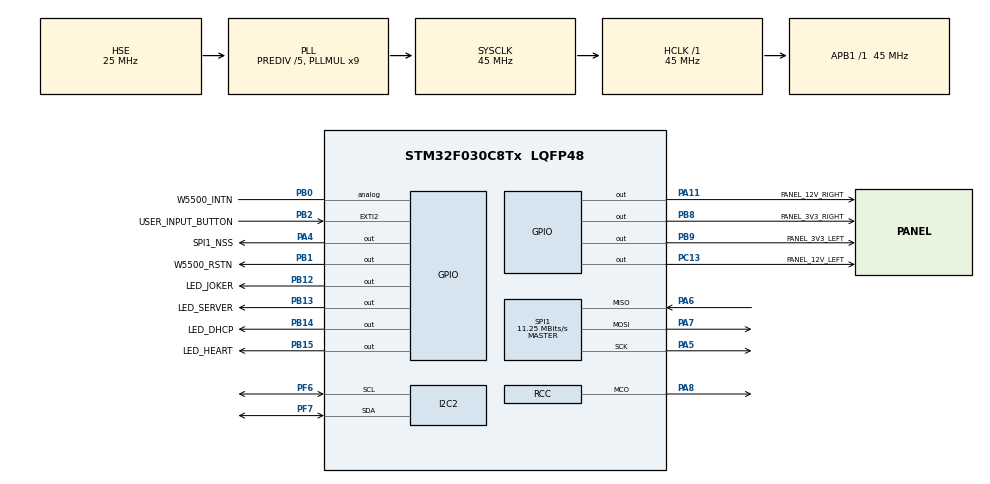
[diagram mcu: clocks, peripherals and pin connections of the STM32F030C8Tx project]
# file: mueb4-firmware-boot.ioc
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I2C2.I2C_Fall_Time=0
I2C2.I2C_Rise_Time=0
I2C2.Speed=100
I2C2.Timing=0xC0000E12
Mcu.Family=STM32F0
Mcu.Name=STM32F030C8Tx
Mcu.Package=LQFP48
Mcu.UserConstants=PRESCALER,45000 - 1;SECOND,1000 - 1
NVIC.EXTI2_3_IRQn=true\:3\:0\:true\:false\:true\:true\:true\:true
NVIC.TIM6_IRQn=true\:2\:0\:true\:false\:true\:true\:true\:true
PA0.GPIO_Label=PANEL_ADC_3V3_LEFT
PA0.GPIO_Mode=GPIO_MODE_ANALOG
PA0.GPIO_PuPd=GPIO_NOPULL
PA0.Signal=ADC_IN0
PA1.GPIO_Label=PANEL_ADC_3V3_RIGHT
PA1.GPIO_Mode=GPIO_MODE_ANALOG
PA1.GPIO_PuPd=GPIO_NOPULL
PA1.Signal=ADC_IN1
PA10.GPIO_Label=PANEL_RX_RIGHT
PA10.GPIO_PuPd=GPIO_PULLUP
PA10.GPIO_Speed=GPIO_SPEED_FREQ_HIGH
PA10.Signal=USART1_RX
PA11.GPIO_Label=PANEL_12V_RIGHT
PA11.Signal=GPIO_Output
PA13.Mode=Serial_Wire
PA13.Signal=SYS_SWDIO
PA14.Mode=Serial_Wire
PA14.Signal=SYS_SWCLK
PA2.GPIO_Label=PANEL_TX_LEFT
PA2.GPIO_Speed=GPIO_SPEED_FREQ_HIGH
PA2.Signal=USART2_TX
PA3.GPIO_Label=PANEL_RX_LEFT
PA3.GPIO_PuPd=GPIO_PULLUP
PA3.GPIO_Speed=GPIO_SPEED_FREQ_HIGH
PA3.Signal=USART2_RX
PA4.GPIO_Label=SPI1_NSS
PA4.Signal=GPIO_Output
PA5.GPIO_PuPd=GPIO_PULLUP
PA5.GPIO_Speed=GPIO_SPEED_FREQ_HIGH
PA5.Mode=Full_Duplex_Master
PA5.Signal=SPI1_SCK
PA6.GPIO_PuPd=GPIO_PULLUP
PA6.GPIO_Speed=GPIO_SPEED_FREQ_HIGH
PA6.Mode=Full_Duplex_Master
PA6.Signal=SPI1_MISO
PA7.GPIO_PuPd=GPIO_PULLUP
PA7.GPIO_Speed=GPIO_SPEED_FREQ_HIGH
PA7.Mode=Full_Duplex_Master
PA7.Signal=SPI1_MOSI
PA8.Mode=Clock-out
PA8.Signal=RCC_MCO
PA9.GPIO_Label=PANEL_TX_RIGHT
PA9.GPIO_Speed=GPIO_SPEED_FREQ_HIGH
PA9.Signal=USART1_TX
PB0.GPIO_Label=W5500_INTN
PB0.GPIO_Mode=GPIO_MODE_ANALOG
PB0.GPIO_PuPd=GPIO_NOPULL
PB0.Signal=GPIO_Analog
PB1.GPIO_Label=W5500_RSTN
PB1.PinState=GPIO_PIN_SET
PB1.Signal=GPIO_Output
PB12.GPIO_Label=LED_JOKER
PB12.Signal=GPIO_Output
PB13.GPIO_Label=LED_SERVER
PB13.Signal=GPIO_Output
PB14.GPIO_Label=LED_DHCP
PB14.Signal=GPIO_Output
PB15.GPIO_Label=LED_HEART
PB15.Signal=GPIO_Output
PB2.GPIO_Label=USER_INPUT_BUTTON
PB2.GPIO_PuPd=GPIO_PULLUP
PB2.Signal=GPXTI2
PB8.GPIO_Label=PANEL_3V3_RIGHT
PB8.GPIO_Speed=GPIO_SPEED_FREQ_LOW
PB8.PinState=GPIO_PIN_SET
PB8.Signal=GPIO_Output
PB9.GPIO_Label=PANEL_3V3_LEFT
PB9.GPIO_Speed=GPIO_SPEED_FREQ_LOW
PB9.PinState=GPIO_PIN_SET
PB9.Signal=GPIO_Output
PC13.GPIO_Label=PANEL_12V_LEFT
PC13.Signal=GPIO_Output
PF0-OSC_IN.Mode=HSE-External-Oscillator
PF0-OSC_IN.Signal=RCC_OSC_IN
PF1-OSC_OUT.Mode=HSE-External-Oscillator
PF1-OSC_OUT.Signal=RCC_OSC_OUT
PF6.GPIO_Pu=GPIO_PULLUP
PF6.GPIO_Speed=GPIO_SPEED_FREQ_HIGH
PF6.Mode=I2C
PF6.Signal=I2C2_SCL
PF7.GPIO_Pu=GPIO_PULLUP
PF7.GPIO_Speed=GPIO_SPEED_FREQ_HIGH
PF7.Mode=I2C
PF7.Signal=I2C2_SDA
ProjectManager.HeapSize=0x200
ProjectManager.StackSize=0x400
ProjectManager.TargetToolchain=STM32CubeIDE
RCC.AHBFreq_Value=45000000
RCC.APB1Freq_Value=45000000
RCC.APB1TimFreq_Value=45000000
RCC.EnbaleCSS=true
RCC.HCLKFreq_Value=45000000
RCC.HSE_VALUE=25000000
RCC.PLLDivider=RCC_PREDIV_DIV5
RCC.PLLMUL=RCC_PLL_MUL9
RCC.PLLSourceVirtual=RCC_PLLSOURCE_HSE
RCC.RCC_MCOSource=RCC_MCO1SOURCE_HSE
RCC.SYSCLKFreq_VALUE=45000000
RCC.SYSCLKSource=RCC_SYSCLKSOURCE_PLLCLK
RCC.Usart1ClockSelection=RCC_USART1CLKSOURCE_HSI
SPI1.BaudRatePrescaler=SPI_BAUDRATEPRESCALER_4
SPI1.CLKPolarity=SPI_POLARITY_LOW
SPI1.CalculateBaudRate=11.25 MBits/s
SPI1.DataSize=SPI_DATASIZE_8BIT
SPI1.Direction=SPI_DIRECTION_2LINES
SPI1.Mode=SPI_MODE_MASTER
SPI1.NSSPMode=SPI_NSS_PULSE_DISABLE
SPI1.VirtualType=VM_MASTER
TIM6.Period=SECOND
TIM6.Prescaler=PRESCALER
VP_TIM6_VS_ClockSourceINT.Mode=Enable_Timer
board=mueb4-firmware

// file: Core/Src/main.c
/* USER CODE BEGIN Header */
/**
 ******************************************************************************
 * @file           : main.c
 * @brief          : Main program body
 ******************************************************************************
 * @attention
 *
 * Copyright (c) 2022 STMicroelectronics.
 * All rights reserved.
 *
 * This software is licensed under terms that can be found in the LICENSE file
 * in the root directory of this software component.
 * If no LICENSE file comes with this software, it is provided AS-IS.
 *
 ******************************************************************************
 */
/* USER CODE END Header */
#include "main.h"
#include "i2c.h"
#include "spi.h"
#include "tim.h"
#include "gpio.h"

/* USER CODE BEGIN Includes */
#include <stdint.h>
/* USER CODE END Includes */

/* USER CODE BEGIN PV */
extern uint32_t _app_address[];
extern uint8_t firmware_update_enabler;
/* USER CODE END PV */

void SystemClock_Config(void);
/* USER CODE BEGIN PFP */
void FirmwareUpdater(void);
/* USER CODE END PFP */

int main(void)
{

  /* MCU Configuration--------------------------------------------------------*/

  /* Reset of all peripherals, Initializes the Flash interface and the Systick. */
  HAL_Init();

  /* Configure the system clock */
  SystemClock_Config();

  /* Initialize all configured peripherals */
  MX_TIM6_Init();
  MX_I2C2_Init();
  MX_GPIO_Init();
  MX_SPI1_Init();
  /* USER CODE BEGIN 2 */
  HAL_TIM_Base_Start_IT(&htim6);

  // Wait for user button(enters firmware updater)
  HAL_Delay(1000u);

  /* Test if user code is programmed starting from address "(uint32_t)_appaddr" or firmware update is enabled from app */
  if (((*(__IO uint32_t *)(uint32_t)_app_address) & 0x2FFE0000) != 0x20000000 ||
      firmware_update_enabler == 0xABu) {
    firmware_update_enabler = 0u;
    FirmwareUpdater();
  } else {
    /* Initialize user application's Stack Pointer */
    __set_MSP(*(__IO uint32_t *)(uint32_t)_app_address);

    /* Jump to user application */
    ((void (*)(void)) * (__IO uint32_t *)((uint32_t)_app_address + 4u))();
  }
  /* USER CODE END 2 */

  /* Infinite loop */
  while (1) {

  }
}

void SystemClock_Config(void)
{
  RCC_OscInitTypeDef RCC_OscInitStruct = {0};
  RCC_ClkInitTypeDef RCC_ClkInitStruct = {0};

  /** Initializes the RCC Oscillators according to the specified parameters
  * in the RCC_OscInitTypeDef structure.
  */
  RCC_OscInitStruct.OscillatorType = RCC_OSCILLATORTYPE_HSE;
  RCC_OscInitStruct.HSEState = RCC_HSE_ON;
  RCC_OscInitStruct.PLL.PLLState = RCC_PLL_ON;
  RCC_OscInitStruct.PLL.PLLSource = RCC_PLLSOURCE_HSE;
  RCC_OscInitStruct.PLL.PLLMUL = RCC_PLL_MUL9;
  RCC_OscInitStruct.PLL.PREDIV = RCC_PREDIV_DIV5;
  if (HAL_RCC_OscConfig(&RCC_OscInitStruct) != HAL_OK)
  {
    Error_Handler();
  }

  /** Initializes the CPU, AHB and APB buses clocks
  */
  RCC_ClkInitStruct.ClockType = RCC_CLOCKTYPE_HCLK|RCC_CLOCKTYPE_SYSCLK
                              |RCC_CLOCKTYPE_PCLK1;
  RCC_ClkInitStruct.SYSCLKSource = RCC_SYSCLKSOURCE_PLLCLK;
  RCC_ClkInitStruct.AHBCLKDivider = RCC_SYSCLK_DIV1;
  RCC_ClkInitStruct.APB1CLKDivider = RCC_HCLK_DIV1;

  if (HAL_RCC_ClockConfig(&RCC_ClkInitStruct, FLASH_LATENCY_1) != HAL_OK)
  {
    Error_Handler();
  }
  HAL_RCC_MCOConfig(RCC_MCO, RCC_MCO1SOURCE_HSE, RCC_MCODIV_1);

  /** Enables the Clock Security System
  */
  HAL_RCC_EnableCSS();
}

void Error_Handler(void)
{
  __disable_irq();
  while (1) {
  }
}

#ifdef  USE_FULL_ASSERT
/**
  * @brief  Reports the name of the source file and the source line number
  *         where the assert_param error has occurred.
  * @param  file: pointer to the source file name
  * @param  line: assert_param error line source number
  * @retval None
  */
void assert_failed(uint8_t *file, uint32_t line)
{
  /* USER CODE BEGIN 6 */
  /* User can add his own implementation to report the file name and line
     number,
     ex: printf("Wrong parameters value: file %s on line %d\r\n", file, line) */
  /* USER CODE END 6 */
}
#endif /* USE_FULL_ASSERT */
